# ATSAM4LC2B register map
Vendor: Atmel Corporation; Series: SAM4L; File version: B
CPU: CM4 r0p1, little endian, MPU, no FPU, 4 interrupt priority bits
Registers are 32-bit, write-only, reset 0x0 unless marked. A register's access mark holds for its fields unless they carry their own. Offsets are from the block's base; [hi:lo] are bit positions; {n}, {i} and the like mark numbered series; 'fields as' and 'values as' point back to an identical list.

## USART0 — Universal Synchronous Asynchronous Receiver Transmitter 0
Base 0x40024000; register names take the prefix USART_
Same registers: USART1 0x40028000, USART2 0x4002C000, USART3 0x40030000
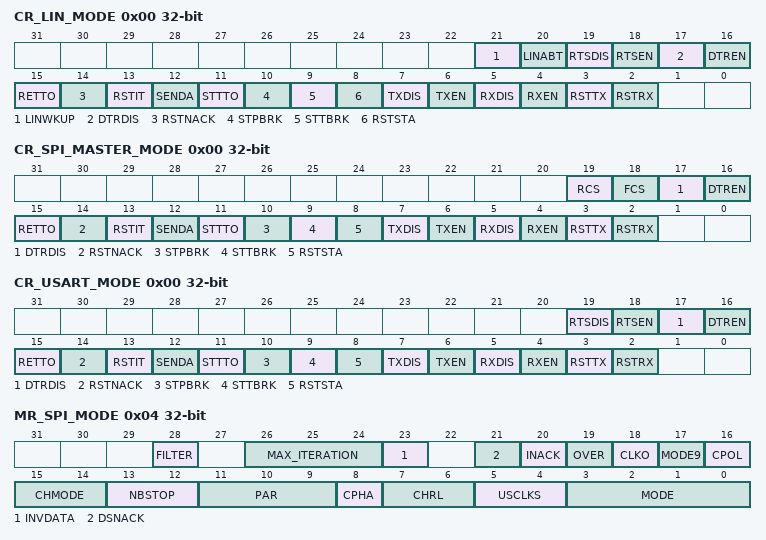
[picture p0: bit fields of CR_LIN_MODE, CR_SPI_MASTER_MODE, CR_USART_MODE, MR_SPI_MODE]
0x00 CR_LIN_MODE (alternate view of CR) — Control Register
  [21] LINWKUP — Sends a wakeup signal on the LIN bus
  [20] LINABT — Abort the current LIN transmission
  [19] RTSDIS — Request to Send Disable
    0=No effect; 1=Drives the pin RTS to 1
  [18] RTSEN — Request to Send Enable
    0=No effect; 1=Drives the pin RTS to 0
  [17] DTRDIS — Data Terminal Ready Disable
    0=No effect; 1=Drives the pin DTR to 1
  [16] DTREN — Data Terminal Ready Enable
    0=No effect; 1=Drives the pin DTR at 0
  [15] RETTO — Rearm Time-out
    0=No effect; 1=Restart Time-out
  [14] RSTNACK — Reset Non Acknowledge
    0=No effect; 1=Resets NACK in CSR
  [13] RSTIT — Reset Iterations
    0=No effect; 1=Resets ITERATION in CSR. No effect if the ISO7816 is not enabled
  [12] SENDA — Send Address
    0=No effect; 1=In Multi-drop Mode only, the next character written to the THR is sent with the address bit set
  [11] STTTO — Start Time-out
    0=No effect; 1=Starts waiting for a character before clocking the time-out counter
  [10] STPBRK — Stop Break
    0=No effect; 1=Stops transmission of the break after a minimum of one character length and transmits a high level during 12-bit periods.No effect if no break is being transmitted
  [9] STTBRK — Start Break
    0=No effect; 1=Starts transmission of a break after the characters present in THR and the Transmit Shift Register have been transmitted. No effect if a break is already being transmitted
  [8] RSTSTA — Reset Status Bits
    0=No effect; 1=Resets the status bits PARE, FRAME, OVRE and RXBRK in the CSR
  [7] TXDIS — Transmitter Disable
    0=No effect; 1=Disables the transmitter
  [6] TXEN — Transmitter Enable
    0=No effect; 1=Enables the transmitter if TXDIS is 0
  [5] RXDIS — Receiver Disable
    0=No effect; 1=Disables the receiver
  [4] RXEN — Receiver Enable
    0=No effect; 1=Enables the receiver, if RXDIS is 0
  [3] RSTTX — Reset Transmitter
    0=No effect; 1=Resets the transmitter
  [2] RSTRX — Reset Receiver
    0=No effect; 1=Resets the receiver
0x00 CR_SPI_MASTER_MODE (alternate view of CR) — Control Register
  [19] RCS — Release SPI Chip Select
    0=No effect; 1=Releases the Slave Select Line NSS (RTS pin)
  [18] FCS — Force SPI Chip Select
    0=No effect; 1=Forces the Slave Select Line NSS (RTS pin) to 0, even if USART is no transmitting, in order to address SPI slave devices supporting the CSAAT Mode (Chip Select Active After Transfer)
  [17] DTRDIS — Data Terminal Ready Disable
    0=No effect; 1=Drives the pin DTR to 1
  [16] DTREN — Data Terminal Ready Enable
    0=No effect; 1=Drives the pin DTR at 0
  [15] RETTO — Rearm Time-out
    0=No effect; 1=Restart Time-out
  [14] RSTNACK — Reset Non Acknowledge
    0=No effect; 1=Resets NACK in CSR
  [13] RSTIT — Reset Iterations
    values as CR_LIN_MODE.RSTIT
  [12] SENDA — Send Address
    values as CR_LIN_MODE.SENDA
  [11] STTTO — Start Time-out
    values as CR_LIN_MODE.STTTO
  [10] STPBRK — Stop Break
    values as CR_LIN_MODE.STPBRK
  [9] STTBRK — Start Break
    values as CR_LIN_MODE.STTBRK
  [8] RSTSTA — Reset Status Bits
    values as CR_LIN_MODE.RSTSTA
  [7] TXDIS — Transmitter Disable
    0=No effect; 1=Disables the transmitter
  [6] TXEN — Transmitter Enable
    0=No effect; 1=Enables the transmitter if TXDIS is 0
  [5] RXDIS — Receiver Disable
    0=No effect; 1=Disables the receiver
  [4] RXEN — Receiver Enable
    0=No effect; 1=Enables the receiver, if RXDIS is 0
  [3] RSTTX — Reset Transmitter
    0=No effect; 1=Resets the transmitter
  [2] RSTRX — Reset Receiver
    0=No effect; 1=Resets the receiver
0x00 CR_USART_MODE (alternate view of CR) — Control Register
  [19] RTSDIS — Request to Send Disable
    0=No effect; 1=Drives the pin RTS to 1
  [18] RTSEN — Request to Send Enable
    0=No effect; 1=Drives the pin RTS to 0
  [17] DTRDIS — Data Terminal Ready Disable
    0=No effect; 1=Drives the pin DTR to 1
  [16] DTREN — Data Terminal Ready Enable
    0=No effect; 1=Drives the pin DTR at 0
  [15] RETTO — Rearm Time-out
    0=No effect; 1=Restart Time-out
  [14] RSTNACK — Reset Non Acknowledge
    0=No effect; 1=Resets NACK in CSR
  [13] RSTIT — Reset Iterations
    values as CR_LIN_MODE.RSTIT
  [12] SENDA — Send Address
    values as CR_LIN_MODE.SENDA
  [11] STTTO — Start Time-out
    values as CR_LIN_MODE.STTTO
  [10] STPBRK — Stop Break
    values as CR_LIN_MODE.STPBRK
  [9] STTBRK — Start Break
    values as CR_LIN_MODE.STTBRK
  [8] RSTSTA — Reset Status Bits
    values as CR_LIN_MODE.RSTSTA
  [7] TXDIS — Transmitter Disable
    0=No effect; 1=Disables the transmitter
  [6] TXEN — Transmitter Enable
    0=No effect; 1=Enables the transmitter if TXDIS is 0
  [5] RXDIS — Receiver Disable
    0=No effect; 1=Disables the receiver
  [4] RXEN — Receiver Enable
    0=No effect; 1=Enables the receiver, if RXDIS is 0
  [3] RSTTX — Reset Transmitter
    0=No effect; 1=Resets the transmitter
  [2] RSTRX — Reset Receiver
    0=No effect; 1=Resets the receiver
0x04 MR_SPI_MODE rw (alternate view of MR) — Mode Register
  [28] FILTER — Infrared Receive Line Filter
    0=The USART does not filter the receive line; 1=The USART filters the receive line using a three-sample filter (1/16-bit clock) (2 over 3 majority)
  [26:24] MAX_ITERATION — Max interation
  [23] INVDATA — Inverted data
  [21] DSNACK — Disable Successive NACK
    0=NACK is sent on the ISO line as soon as a parity error occurs in the received character (unless INACK is set); 1=Successive parity errors are counted up to the value specified in the MAX_ITERATION field. These parity errors generatea NACK on the ISO line. As soon as this value is reached, no additional NACK is sent on the ISO line. The flag ITERATION is asserted
  [20] INACK — Inhibit Non Acknowledge
    0=The NACK is generated; 1=The NACK is not generated
  [19] OVER — Oversampling Mode
    0=X16 (16x Oversampling); 1=X8 (8x Oversampling)
  [18] CLKO — Clock Output Select
    0=The USART does not drive the SCK pin; 1=The USART drives the SCK pin if USCLKS does not select the external clock SCK
  [17] MODE9 — 9-bit Character Length
    0=CHRL defines character length; 1=9-bit character length
  [16] CPOL — SPI Clock Polarity
    0=ZERO (The inactive state value of SPCK is logic level zero); 1=ONE (The inactive state value of SPCK is logic level one)
  [15:14] CHMODE — Channel Mode
    0=NORMAL (Normal Mode); 1=ECHO (Automatic Echo. Receiver input is connected to the TXD pin); 2=LOCAL_LOOP (Local Loopback. Transmitter output is connected to the Receiver Input); 3=REMOTE_LOOP (Remote Loopback. RXD pin is internally connected to the TXD pin)
  [13:12] NBSTOP — Number of Stop Bits
    0=1 stop bit; 1=1_5 (1.5 stop bits (Only valid if SYNC=0)); 2=2 stop bits
  [11:9] PAR — Parity Type
    0=EVEN (Even parity); 1=ODD (Odd parity); 2=SPACE (Parity forced to 0 (Space)); 3=MARK (Parity forced to 1 (Mark)); 4=NONE (No Parity); 5=No Parity; 6=MULTI (Multi-drop mode); 7=Multi-drop mode
  [8] CPHA — SPI CLock Phase
    0=Data is changed on the leading edge of SPCK and captured on the following edge of SPCK; 1=Data is captured on the leading edge of SPCK and changed on the following edge of SPCK
  [7:6] CHRL — Character Length.
    {v}={v+5} bits (v=0..3)
  [5:4] USCLKS — Clock Selection
    0=MCK; 1=MCK_DIV; 3=SCK
  [3:0] MODE — Usart Mode
    0=NORMAL; 1=RS485; 2=HARDWARE (Hardware Handshaking); 3=MODEM; 4=ISO7816_T0 (IS07816 Protocol: T = 0); 6=ISO7816_T1 (IS07816 Protocol: T = 1); 8=IRDA; 10=LIN_Master; 11=LIN_Slave; 14=SPI_Master; 15=SPI_Slave
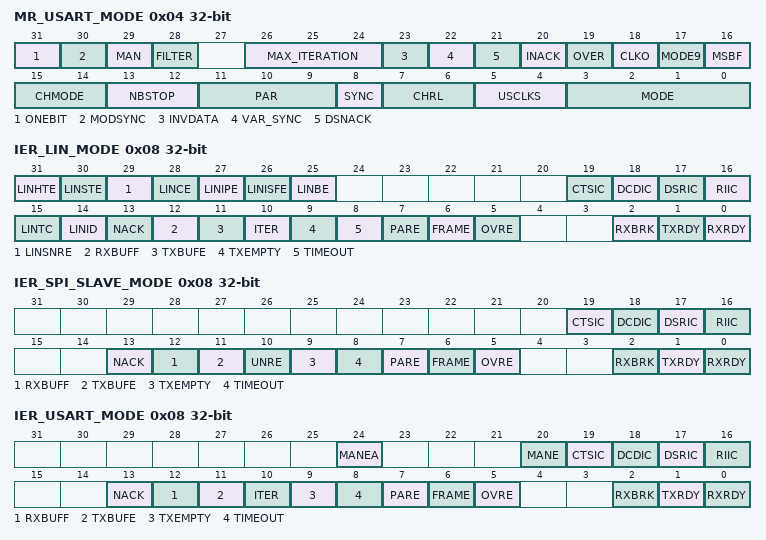
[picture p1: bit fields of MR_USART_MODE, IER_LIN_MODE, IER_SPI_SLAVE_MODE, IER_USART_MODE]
0x04 MR_USART_MODE rw (alternate view of MR) — Mode Register
  [31] ONEBIT — Start Frame Delimiter selector
    0=Start Frame delimiter is COMMAND or DATA SYNC; 1=Start Frame delimiter is One Bit
  [30] MODSYNC — Manchester Synchronization Mode
    0=The Manchester Start bit is a 0 to 1 transition; 1=The Manchester Start bit is a 1 to 0 transition
  [29] MAN — Manchester Encoder/Decoder Enable
    0=Manchester Encoder/Decoder is disabled; 1=Manchester Encoder/Decoder is enabled
  [28] FILTER — Infrared Receive Line Filter
    values as MR_SPI_MODE.FILTER
  [26:24] MAX_ITERATION — Max interation
  [23] INVDATA — Inverted data
  [22] VAR_SYNC — Variable synchronization of command/data sync Start Frame Delimiter
    0=User defined configuration of command or data sync field depending on SYNC value; 1=The sync field is updated when a character is written into THR register
  [21] DSNACK — Disable Successive NACK
    values as MR_SPI_MODE.DSNACK
  [20] INACK — Inhibit Non Acknowledge
    0=The NACK is generated; 1=The NACK is not generated
  [19] OVER — Oversampling Mode
    0=X16 (16x Oversampling); 1=X8 (8x Oversampling)
  [18] CLKO — Clock Output Select
    values as MR_SPI_MODE.CLKO
  [17] MODE9 — 9-bit Character Length
    0=CHRL defines character length; 1=9-bit character length
  [16] MSBF — Bit Order
    0=LSBF (Least Significant Bit first); 1=MSBF (Most Significant Bit first)
  [15:14] CHMODE — Channel Mode
    values as MR_SPI_MODE.CHMODE
  [13:12] NBSTOP — Number of Stop Bits
    values as MR_SPI_MODE.NBSTOP
  [11:9] PAR — Parity Type
    values as MR_SPI_MODE.PAR
  [8] SYNC — Synchronous Mode Select
    0=USART operates in Synchronous Mode; 1=USART operates in Asynchronous Mode
  [7:6] CHRL — Character Length.
    {v}={v+5} bits (v=0..3)
  [5:4] USCLKS — Clock Selection
    0=MCK; 1=MCK_DIV; 3=SCK
  [3:0] MODE — Usart Mode
    values as MR_SPI_MODE.MODE
0x08 IER_LIN_MODE (alternate view of IER) — Interrupt Enable Register
  [31] LINHTE — LIN Header Timeout Error Interrupt Enable
    0=No Effect; 1=Enables the interrupt
  [30] LINSTE — LIN Synch Tolerance Error Interrupt Enable
    0=No Effect; 1=Enables the interrupt
  [29] LINSNRE — LIN Slave Not Responding Error Interrupt Enable
  [28] LINCE — LIN Checksum Error Interrupt Enable
  [27] LINIPE — LIN Identifier Parity Interrupt Enable
  [26] LINISFE — LIN Inconsistent Synch Field Error Interrupt Enable
  [25] LINBE — LIN Bus Error Interrupt Enable
  [19] CTSIC — Clear to Send Input Change Interrupt Enable
    0=No Effect; 1=Enables the interrupt
  [18] DCDIC — Data Carrier Detect Input Change Interrupt Enable
    0=No Effect; 1=Enables the interrupt
  [17] DSRIC — Data Set Ready Input Change Enable
    0=No Effect; 1=Enables the interrupt
  [16] RIIC — Ring Indicator Input Change Enable
    0=No Effect; 1=Enables the interrupt
  [15] LINTC — LIN Transfer Conpleted Interrupt Enable
  [14] LINID — LIN Identifier Sent or LIN Identifier Received Interrupt Enable
  [13] NACK — Non Acknowledge or LIN Break Sent or LIN Break Received Interrupt Enable
    0=No Effect; 1=Enables the interrupt
  [12] RXBUFF — Buffer Full Interrupt Enable
    0=No Effect; 1=Enables the interrupt
  [11] TXBUFE — Buffer Empty Interrupt Enable
    0=No Effect; 1=Enables the interrupt
  [10] ITER — Iteration Interrupt Enable
    0=No Effect; 1=Enables the interrupt
  [9] TXEMPTY — Transmitter Empty Interrupt Enable
    0=No Effect; 1=Enables the interrupt
  [8] TIMEOUT — Time-out Interrupt Enable
    0=No Effect; 1=Enables the interrupt
  [7] PARE — Parity Error Interrupt Enable
    0=No Effect; 1=Enables the interrupt
  [6] FRAME — Framing Error Interrupt Enable
    0=No Effect; 1=Enables the interrupt
  [5] OVRE — Overrun Error Interrupt Enable
    0=No Effect; 1=Enables the interrupt
  [2] RXBRK — Receiver Break Interrupt Enable
    0=No Effect; 1=Enables the interrupt
  [1] TXRDY — Transmitter Ready Interrupt Enable
    0=No Effect; 1=Enables the interrupt
  [0] RXRDY — Receiver Ready Interrupt Enable
    0=No Effect; 1=Enables the interrupt
0x08 IER_SPI_SLAVE_MODE (alternate view of IER) — Interrupt Enable Register
  [all] fields
    0=No Effect; 1=Enables the interrupt
  [19] CTSIC — Clear to Send Input Change Interrupt Enable
  [18] DCDIC — Data Carrier Detect Input Change Interrupt Enable
  [17] DSRIC — Data Set Ready Input Change Enable
  [16] RIIC — Ring Indicator Input Change Enable
  [13] NACK — Non Acknowledge Interrupt Enable
  [12] RXBUFF — Buffer Full Interrupt Enable
  [11] TXBUFE — Buffer Empty Interrupt Enable
  [10] UNRE — SPI Underrun Error Interrupt Enable
  [9] TXEMPTY — Transmitter Empty Interrupt Enable
  [8] TIMEOUT — Time-out Interrupt Enable
  [7] PARE — Parity Error Interrupt Enable
  [6] FRAME — Framing Error Interrupt Enable
  [5] OVRE — Overrun Error Interrupt Enable
  [2] RXBRK — Receiver Break Interrupt Enable
  [1] TXRDY — Transmitter Ready Interrupt Enable
  [0] RXRDY — Receiver Ready Interrupt Enable
0x08 IER_USART_MODE (alternate view of IER) — Interrupt Enable Register
  [24] MANEA — Manchester Error Interrupt Enable
    0=No effect; 1=Enables the interrupt
  [20] MANE — Manchester Error Interrupt Enable
  [19] CTSIC — Clear to Send Input Change Interrupt Enable
    0=No Effect; 1=Enables the interrupt
  [18] DCDIC — Data Carrier Detect Input Change Interrupt Enable
    0=No Effect; 1=Enables the interrupt
  [17] DSRIC — Data Set Ready Input Change Enable
    0=No Effect; 1=Enables the interrupt
  [16] RIIC — Ring Indicator Input Change Enable
    0=No Effect; 1=Enables the interrupt
  [13] NACK — Non Acknowledge Interrupt Enable
    0=No Effect; 1=Enables the interrupt
  [12] RXBUFF — Buffer Full Interrupt Enable
    0=No Effect; 1=Enables the interrupt
  [11] TXBUFE — Buffer Empty Interrupt Enable
    0=No Effect; 1=Enables the interrupt
  [10] ITER — Iteration Interrupt Enable
    0=No Effect; 1=Enables the interrupt
  [9] TXEMPTY — Transmitter Empty Interrupt Enable
    0=No Effect; 1=Enables the interrupt
  [8] TIMEOUT — Time-out Interrupt Enable
    0=No Effect; 1=Enables the interrupt
  [7] PARE — Parity Error Interrupt Enable
    0=No Effect; 1=Enables the interrupt
  [6] FRAME — Framing Error Interrupt Enable
    0=No Effect; 1=Enables the interrupt
  [5] OVRE — Overrun Error Interrupt Enable
    0=No Effect; 1=Enables the interrupt
  [2] RXBRK — Receiver Break Interrupt Enable
    0=No Effect; 1=Enables the interrupt
  [1] TXRDY — Transmitter Ready Interrupt Enable
    0=No Effect; 1=Enables the interrupt
  [0] RXRDY — Receiver Ready Interrupt Enable
    0=No Effect; 1=Enables the interrupt
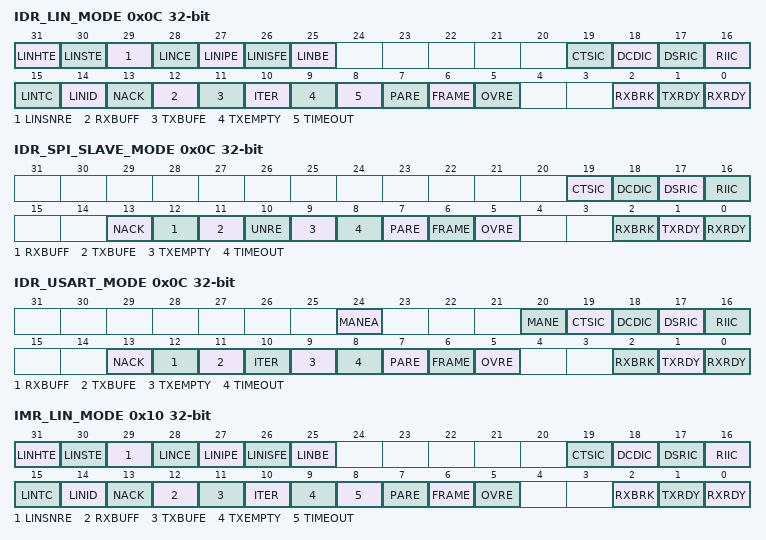
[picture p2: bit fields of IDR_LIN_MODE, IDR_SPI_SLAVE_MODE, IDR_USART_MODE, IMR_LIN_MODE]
0x0C IDR_LIN_MODE (alternate view of IDR) — Interrupt Disable Register
  [31] LINHTE — LIN Header Timeout Error Interrupt Disable
    0=No Effect; 1=Disables the interrupt
  [30] LINSTE — LIN Synch Tolerance Error Interrupt Disable
    0=No Effect; 1=Disables the interrupt
  [29] LINSNRE — LIN Slave Not Responding Error Interrupt Disable
  [28] LINCE — LIN Checksum Error Interrupt Disable
  [27] LINIPE — LIN Identifier Parity Interrupt Disable
  [26] LINISFE — LIN Inconsistent Synch Field Error Interrupt Disable
  [25] LINBE — LIN Bus Error Interrupt Disable
  [19] CTSIC — Clear to Send Input Change Interrupt Disable
    0=No Effect; 1=Disables the interrupt
  [18] DCDIC — Data Carrier Detect Input Change Interrupt Disable
    0=No Effect; 1=Disables the interrupt
  [17] DSRIC — Data Set Ready Input Change Disable
    0=No Effect; 1=Disables the interrupt
  [16] RIIC — Ring Indicator Input Change Disable
    0=No Effect; 1=Disables the interrupt
  [15] LINTC — LIN Transfer Conpleted Interrupt Disable
  [14] LINID — LIN Identifier Sent or LIN Identifier Received Interrupt Disable
  [13] NACK — Non Acknowledge or LIN Break Sent or LIN Break Received Interrupt Disable
    0=No Effect; 1=Disables the interrupt
  [12] RXBUFF — Buffer Full Interrupt Disable
    0=No Effect; 1=Disables the interrupt
  [11] TXBUFE — Buffer Empty Interrupt Disable
    0=No Effect; 1=Disables the interrupt
  [10] ITER — Iteration Interrupt Disable
    0=No Effect; 1=Disables the interrupt
  [9] TXEMPTY — Transmitter Empty Interrupt Disable
    0=No Effect; 1=Disables the interrupt
  [8] TIMEOUT — Time-out Interrupt Disable
    0=No Effect; 1=Disables the interrupt
  [7] PARE — Parity Error Interrupt Disable
    0=No Effect; 1=Disables the interrupt
  [6] FRAME — Framing Error Interrupt Disable
    0=No Effect; 1=Disables the interrupt
  [5] OVRE — Overrun Error Interrupt Disable
    0=No Effect; 1=Disables the interrupt
  [2] RXBRK — Receiver Break Interrupt Disable
    0=No Effect; 1=Disables the interrupt
  [1] TXRDY — Transmitter Ready Interrupt Disable
    0=No Effect; 1=Disables the interrupt
  [0] RXRDY — Receiver Ready Interrupt Disable
    0=No Effect; 1=Disables the interrupt
0x0C IDR_SPI_SLAVE_MODE (alternate view of IDR) — Interrupt Disable Register
  [all] fields
    0=No Effect; 1=Disables the interrupt
  [19] CTSIC — Clear to Send Input Change Interrupt Disable
  [18] DCDIC — Data Carrier Detect Input Change Interrupt Disable
  [17] DSRIC — Data Set Ready Input Change Disable
  [16] RIIC — Ring Indicator Input Change Disable
  [13] NACK — Non Acknowledge Interrupt Disable
  [12] RXBUFF — Buffer Full Interrupt Disable
  [11] TXBUFE — Buffer Empty Interrupt Disable
  [10] UNRE — SPI Underrun Error Interrupt Disable
  [9] TXEMPTY — Transmitter Empty Interrupt Disable
  [8] TIMEOUT — Time-out Interrupt Disable
  [7] PARE — Parity Error Interrupt Disable
  [6] FRAME — Framing Error Interrupt Disable
  [5] OVRE — Overrun Error Interrupt Disable
  [2] RXBRK — Receiver Break Interrupt Disable
  [1] TXRDY — Transmitter Ready Interrupt Disable
  [0] RXRDY — Receiver Ready Interrupt Disable
0x0C IDR_USART_MODE (alternate view of IDR) — Interrupt Disable Register
  [24] MANEA — Manchester Error Interrupt Disable
    0=No effect; 1=Disables the corresponding interrupt
  [20] MANE — Manchester Error Interrupt Disable
  [19] CTSIC — Clear to Send Input Change Interrupt Disable
    0=No Effect; 1=Disables the interrupt
  [18] DCDIC — Data Carrier Detect Input Change Interrupt Disable
    0=No Effect; 1=Disables the interrupt
  [17] DSRIC — Data Set Ready Input Change Disable
    0=No Effect; 1=Disables the interrupt
  [16] RIIC — Ring Indicator Input Change Disable
    0=No Effect; 1=Disables the interrupt
  [13] NACK — Non Acknowledge Interrupt Disable
    0=No Effect; 1=Disables the interrupt
  [12] RXBUFF — Buffer Full Interrupt Disable
    0=No Effect; 1=Disables the interrupt
  [11] TXBUFE — Buffer Empty Interrupt Disable
    0=No Effect; 1=Disables the interrupt
  [10] ITER — Iteration Interrupt Disable
    0=No Effect; 1=Disables the interrupt
  [9] TXEMPTY — Transmitter Empty Interrupt Disable
    0=No Effect; 1=Disables the interrupt
  [8] TIMEOUT — Time-out Interrupt Disable
    0=No Effect; 1=Disables the interrupt
  [7] PARE — Parity Error Interrupt Disable
    0=No Effect; 1=Disables the interrupt
  [6] FRAME — Framing Error Interrupt Disable
    0=No Effect; 1=Disables the interrupt
  [5] OVRE — Overrun Error Interrupt Disable
    0=No Effect; 1=Disables the interrupt
  [2] RXBRK — Receiver Break Interrupt Disable
    0=No Effect; 1=Disables the interrupt
  [1] TXRDY — Transmitter Ready Interrupt Disable
    0=No Effect; 1=Disables the interrupt
  [0] RXRDY — Receiver Ready Interrupt Disable
    0=No Effect; 1=Disables the interrupt
0x10 IMR_LIN_MODE ro (alternate view of IMR) — Interrupt Mask Register
  [31] LINHTE — LIN Header Timeout Error Interrupt Mask
    0=The interrupt is disabled; 1=The interrupt is enabled
  [30] LINSTE — LIN Synch Tolerance Error Interrupt Mask
    0=The interrupt is disabled; 1=The interrupt is enabled
  [29] LINSNRE — LIN Slave Not Responding Error Interrupt Mask
  [28] LINCE — LIN Checksum Error Interrupt Mask
  [27] LINIPE — LIN Identifier Parity Interrupt Mask
  [26] LINISFE — LIN Inconsistent Synch Field Error Interrupt Mask
  [25] LINBE — LIN Bus Error Interrupt Mask
  [19] CTSIC — Clear to Send Input Change Interrupt Mask
    0=The interrupt is disabled; 1=The interrupt is enabled
  [18] DCDIC — Data Carrier Detect Input Change Interrupt Mask
    0=The interrupt is disabled; 1=The interrupt is enabled
  [17] DSRIC — Data Set Ready Input Change Mask
    0=The interrupt is disabled; 1=The interrupt is enabled
  [16] RIIC — Ring Indicator Input Change Mask
    0=The interrupt is disabled; 1=The interrupt is enabled
  [15] LINTC — LIN Transfer Conpleted Interrupt Mask
  [14] LINID — LIN Identifier Sent or LIN Received Interrupt Mask
  [13] NACK — Non Acknowledge or LIN Break Sent or LIN Break Received Interrupt Mask
    0=The interrupt is disabled; 1=The interrupt is enabled
  [12] RXBUFF — Buffer Full Interrupt Mask
    0=The interrupt is disabled; 1=The interrupt is enabled
  [11] TXBUFE — Buffer Empty Interrupt Mask
    0=The interrupt is disabled; 1=The interrupt is enabled
  [10] ITER — Iteration Interrupt Mask
    0=The interrupt is disabled; 1=The interrupt is enabled
  [9] TXEMPTY — TXEMPTY Interrupt Mask
    0=The interrupt is disabled; 1=The interrupt is enabled
  [8] TIMEOUT — Time-out Interrupt Mask
    0=The interrupt is disabled; 1=The interrupt is enabled
  [7] PARE — Parity Error Interrupt Mask
    0=The interrupt is disabled; 1=The interrupt is enabled
  [6] FRAME — Framing Error Interrupt Mask
    0=The interrupt is disabled; 1=The interrupt is enabled
  [5] OVRE — Overrun Error Interrupt Mask
    0=The interrupt is disabled; 1=The interrupt is enabled
  [2] RXBRK — Receiver Break Interrupt Mask
    0=The interrupt is disabled; 1=The interrupt is enabled
  [1] TXRDY — TXRDY Interrupt Mask
    0=The interrupt is disabled; 1=The interrupt is enabled
  [0] RXRDY — RXRDY Interrupt Mask
    0=The interrupt is disabled; 1=The interrupt is enabled
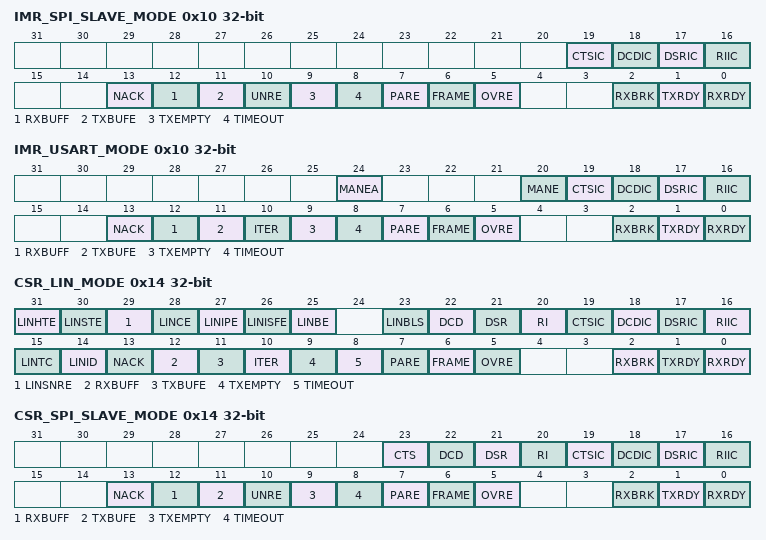
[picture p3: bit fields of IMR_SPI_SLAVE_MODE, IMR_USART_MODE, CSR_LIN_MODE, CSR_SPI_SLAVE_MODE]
0x10 IMR_SPI_SLAVE_MODE ro (alternate view of IMR) — Interrupt Mask Register
  [all] fields
    0=The interrupt is disabled; 1=The interrupt is enabled
  [19] CTSIC — Clear to Send Input Change Interrupt Mask
  [18] DCDIC — Data Carrier Detect Input Change Interrupt Mask
  [17] DSRIC — Data Set Ready Input Change Mask
  [16] RIIC — Ring Indicator Input Change Mask
  [13] NACK — Non Acknowledge Interrupt Mask
  [12] RXBUFF — Buffer Full Interrupt Mask
  [11] TXBUFE — Buffer Empty Interrupt Mask
  [10] UNRE — SPI Underrun Error Interrupt Mask
  [9] TXEMPTY — TXEMPTY Interrupt Mask
  [8] TIMEOUT — Time-out Interrupt Mask
  [7] PARE — Parity Error Interrupt Mask
  [6] FRAME — Framing Error Interrupt Mask
  [5] OVRE — Overrun Error Interrupt Mask
  [2] RXBRK — Receiver Break Interrupt Mask
  [1] TXRDY — TXRDY Interrupt Mask
  [0] RXRDY — RXRDY Interrupt Mask
0x10 IMR_USART_MODE ro (alternate view of IMR) — Interrupt Mask Register
  [24] MANEA — Manchester Error Interrupt Mask
    0=The interrupt is disabled; 1=The interrupt is enabled
  [20] MANE — Manchester Error Interrupt Mask
  [19] CTSIC — Clear to Send Input Change Interrupt Mask
    0=The interrupt is disabled; 1=The interrupt is enabled
  [18] DCDIC — Data Carrier Detect Input Change Interrupt Mask
    0=The interrupt is disabled; 1=The interrupt is enabled
  [17] DSRIC — Data Set Ready Input Change Mask
    0=The interrupt is disabled; 1=The interrupt is enabled
  [16] RIIC — Ring Indicator Input Change Mask
    0=The interrupt is disabled; 1=The interrupt is enabled
  [13] NACK — Non Acknowledge Interrupt Mask
    0=The interrupt is disabled; 1=The interrupt is enabled
  [12] RXBUFF — Buffer Full Interrupt Mask
    0=The interrupt is disabled; 1=The interrupt is enabled
  [11] TXBUFE — Buffer Empty Interrupt Mask
    0=The interrupt is disabled; 1=The interrupt is enabled
  [10] ITER — Iteration Interrupt Mask
    0=The interrupt is disabled; 1=The interrupt is enabled
  [9] TXEMPTY — TXEMPTY Interrupt Mask
    0=The interrupt is disabled; 1=The interrupt is enabled
  [8] TIMEOUT — Time-out Interrupt Mask
    0=The interrupt is disabled; 1=The interrupt is enabled
  [7] PARE — Parity Error Interrupt Mask
    0=The interrupt is disabled; 1=The interrupt is enabled
  [6] FRAME — Framing Error Interrupt Mask
    0=The interrupt is disabled; 1=The interrupt is enabled
  [5] OVRE — Overrun Error Interrupt Mask
    0=The interrupt is disabled; 1=The interrupt is enabled
  [2] RXBRK — Receiver Break Interrupt Mask
    0=The interrupt is disabled; 1=The interrupt is enabled
  [1] TXRDY — TXRDY Interrupt Mask
    0=The interrupt is disabled; 1=The interrupt is enabled
  [0] RXRDY — RXRDY Interrupt Mask
    0=The interrupt is disabled; 1=The interrupt is enabled
0x14 CSR_LIN_MODE ro (alternate view of CSR) — Channel Status Register
  [31] LINHTE — LIN Header Timeout Error
    0=COMM_RX is at 0; 1=COMM_RX is at 1
  [30] LINSTE — LIN Synch Tolerance Error
    0=COMM_TX is at 0; 1=COMM_TX is at 1
  [29] LINSNRE — LIN Slave Not Responding Error
  [28] LINCE — LIN Checksum Error
  [27] LINIPE — LIN Identifier Parity Error
  [26] LINISFE — LIN Inconsistent Synch Field Error
  [25] LINBE — LIN Bit Error
  [23] LINBLS — LIN Bus Line Status
    0=CTS is at 0; 1=CTS is at 1
  [22] DCD — Image of DCD Input
    0=DCD is at 0; 1=DCD is at 1
  [21] DSR — Image of DSR Input
    0=DSR is at 0; 1=DSR is at 1
  [20] RI — Image of RI Input
    0=RI is at 0; 1=RI is at 1
  [19] CTSIC — Clear to Send Input Change Flag
    0=No input change has been detected on the CTS pin since the last read of CSR; 1=At least one input change has been detected on the CTS pin since the last read of CSR
  [18] DCDIC — Data Carrier Detect Input Change Flag
    0=No input change has been detected on the DCD pin since the last read of CSR; 1=At least one input change has been detected on the DCD pin since the last read of CSR
  [17] DSRIC — Data Set Ready Input Change Flag
    0=No input change has been detected on the DSR pin since the last read of CSR; 1=At least one input change has been detected on the DSR pin since the last read of CSR
  [16] RIIC — Ring Indicator Input Change Flag
    0=No input change has been detected on the RI pin since the last read of CSR; 1=At least one input change has been detected on the RI pin since the last read of CSR
  [15] LINTC — LIN Transfer Conpleted
  [14] LINID — LIN Identifier Sent or LIN Identifier Received
  [13] NACK — Non Acknowledge or LIN Break Sent or LIN Break Received
    0=No Non Acknowledge has not been detected since the last RSTNACK; 1=At least one Non Acknowledge has been detected since the last RSTNACK
  [12] RXBUFF — Reception Buffer Full
    0=The signal Buffer Full from the Receive PDC channel is inactive; 1=The signal Buffer Full from the Receive PDC channel is active
  [11] TXBUFE — Transmission Buffer Empty
    0=The signal Buffer Empty from the Transmit PDC channel is inactive; 1=The signal Buffer Empty from the Transmit PDC channel is active
  [10] ITER — Max number of Repetitions Reached
    0=Maximum number of repetitions has not been reached since the last RSIT; 1=Maximum number of repetitions has been reached since the last RSIT
  [9] TXEMPTY — Transmitter Empty
    0=There are characters in either THR or the Transmit Shift Register, or the transmitter is disabled; 1=There is at least one character in either THR or the Transmit Shift Register
  [8] TIMEOUT — Receiver Time-out
    0=There has not been a time-out since the last Start Time-out command or the Time-out Register is 0; 1=There has been a time-out since the last Start Time-out command
  [7] PARE — Parity Error
    0=No parity error has been detected since the last RSTSTA; 1=At least one parity error has been detected since the last RSTSTA
  [6] FRAME — Framing Error
    0=No stop bit has been detected low since the last RSTSTA; 1=At least one stop bit has been detected low since the last RSTSTA
  [5] OVRE — Overrun Error
    0=No overrun error has occurred since since the last RSTSTA; 1=At least one overrun error has occurred since the last RSTSTA
  [2] RXBRK — Break Received/End of Break
    0=No Break received or End of Break detected since the last RSTSTA; 1=Break Received or End of Break detected since the last RSTSTA
  [1] TXRDY — Transmitter Ready
    0=A character is in the THR waiting to be transferred to the Transmit Shift Register, or an STTBRK command has been requested, or the transmitter is disabled. As soon as the transmitter is enabled, TXRDY becomes 1; 1=There is no character in the THR
  [0] RXRDY — Receiver Ready
    0=No complete character has been received since the last read of RHR or the receiver is disabled. If characters werebeing received when the receiver was disabled, RXRDY changes to 1 when the receiver is enabled; 1=At least one complete character has been received and RHR has not yet been read
0x14 CSR_SPI_SLAVE_MODE ro (alternate view of CSR) — Channel Status Register
  [23] CTS — Image of CTS Input
    0=CTS is at 0; 1=CTS is at 1
  [22] DCD — Image of DCD Input
    0=DCD is at 0; 1=DCD is at 1
  [21] DSR — Image of DSR Input
    0=DSR is at 0; 1=DSR is at 1
  [20] RI — Image of RI Input
    0=RI is at 0; 1=RI is at 1
  [19] CTSIC — Clear to Send Input Change Flag
    values as CSR_LIN_MODE.CTSIC
  [18] DCDIC — Data Carrier Detect Input Change Flag
    values as CSR_LIN_MODE.DCDIC
  [17] DSRIC — Data Set Ready Input Change Flag
    values as CSR_LIN_MODE.DSRIC
  [16] RIIC — Ring Indicator Input Change Flag
    values as CSR_LIN_MODE.RIIC
  [13] NACK — Non Acknowledge
    values as CSR_LIN_MODE.NACK
  [12] RXBUFF — Reception Buffer Full
    values as CSR_LIN_MODE.RXBUFF
  [11] TXBUFE — Transmission Buffer Empty
    values as CSR_LIN_MODE.TXBUFE
  [10] UNRE — SPI Underrun Error
    0=No SPI underrun error has occurred since the last RSTSTA; 1=At least one SPI underrun error has occurred since the last RSTSTA
  [9] TXEMPTY — Transmitter Empty
    values as CSR_LIN_MODE.TXEMPTY
  [8] TIMEOUT — Receiver Time-out
    values as CSR_LIN_MODE.TIMEOUT
  [7] PARE — Parity Error
    values as CSR_LIN_MODE.PARE
  [6] FRAME — Framing Error
    values as CSR_LIN_MODE.FRAME
  [5] OVRE — Overrun Error
    values as CSR_LIN_MODE.OVRE
  [2] RXBRK — Break Received/End of Break
    values as CSR_LIN_MODE.RXBRK
  [1] TXRDY — Transmitter Ready
    values as CSR_LIN_MODE.TXRDY
  [0] RXRDY — Receiver Ready
    values as CSR_LIN_MODE.RXRDY
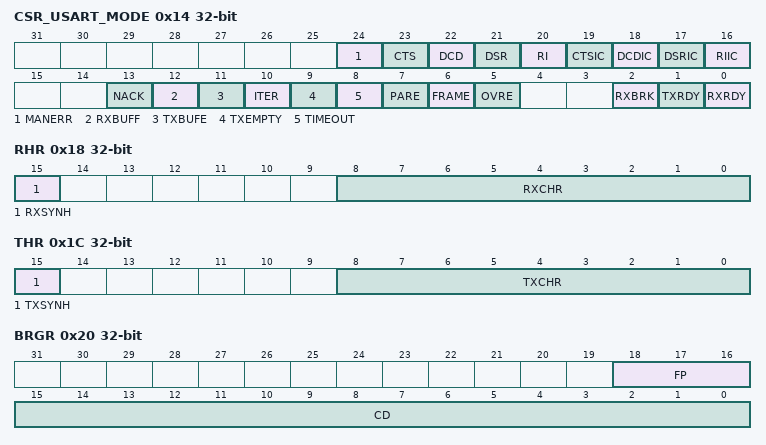
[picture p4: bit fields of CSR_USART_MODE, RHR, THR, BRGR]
0x14 CSR_USART_MODE ro (alternate view of CSR) — Channel Status Register
  [24] MANERR — Manchester Error
    0=No Manchester error has been detected since the last RSTSTA; 1=At least one Manchester error has been detected since the last RSTSTA
  [23] CTS — Image of CTS Input
    0=CTS is at 0; 1=CTS is at 1
  [22] DCD — Image of DCD Input
    0=DCD is at 0; 1=DCD is at 1
  [21] DSR — Image of DSR Input
    0=DSR is at 0; 1=DSR is at 1
  [20] RI — Image of RI Input
    0=RI is at 0; 1=RI is at 1
  [19] CTSIC — Clear to Send Input Change Flag
    values as CSR_LIN_MODE.CTSIC
  [18] DCDIC — Data Carrier Detect Input Change Flag
    values as CSR_LIN_MODE.DCDIC
  [17] DSRIC — Data Set Ready Input Change Flag
    values as CSR_LIN_MODE.DSRIC
  [16] RIIC — Ring Indicator Input Change Flag
    values as CSR_LIN_MODE.RIIC
  [13] NACK — Non Acknowledge
    values as CSR_LIN_MODE.NACK
  [12] RXBUFF — Reception Buffer Full
    values as CSR_LIN_MODE.RXBUFF
  [11] TXBUFE — Transmission Buffer Empty
    values as CSR_LIN_MODE.TXBUFE
  [10] ITER — Max number of Repetitions Reached
    values as CSR_LIN_MODE.ITER
  [9] TXEMPTY — Transmitter Empty
    values as CSR_LIN_MODE.TXEMPTY
  [8] TIMEOUT — Receiver Time-out
    values as CSR_LIN_MODE.TIMEOUT
  [7] PARE — Parity Error
    values as CSR_LIN_MODE.PARE
  [6] FRAME — Framing Error
    values as CSR_LIN_MODE.FRAME
  [5] OVRE — Overrun Error
    values as CSR_LIN_MODE.OVRE
  [2] RXBRK — Break Received/End of Break
    values as CSR_LIN_MODE.RXBRK
  [1] TXRDY — Transmitter Ready
    values as CSR_LIN_MODE.TXRDY
  [0] RXRDY — Receiver Ready
    values as CSR_LIN_MODE.RXRDY
0x18 RHR ro — Receiver Holding Register
  [15] RXSYNH — Received Sync
    0=Last character received is a Data; 1=Last character received is a Command
  [8:0] RXCHR — Received Character
0x1C THR — Transmitter Holding Register
  [15] TXSYNH — Sync Field to be transmitted
    0=The next character sent is encoded as a data. Start Frame Delimiter is DATA SYNC; 1=The next character sent is encoded as a command. Start Frame Delimiter is COMMAND SYNC
  [8:0] TXCHR — Character to be Transmitted
0x20 BRGR rw — Baud Rate Generator Register
  [18:16] FP — Fractional Part
    0=Fractional divider is disabled
  [15:0] CD — Clock Divisor
    0=DISABLE (Disables the clock); 1=BYPASS (Clock Divisor Bypass); 2=Baud Rate (Asynchronous Mode) = Selected Clock/(16 x CD) or (8 x CD); Baud Rate (Synchronous Mode) = Selected Clock/CD;
0x24 RTOR rw — Receiver Time-out Register
  [16:0] TO — Time-out Value
    0=DISABLE (Disables the RX Time-out function)
0x28 TTGR rw — Transmitter Timeguard Register
  [7:0] TG — Timeguard Value
    0=DISABLE (Disables the TX Timeguard function.)
0x40 FIDI rw reset 0x174 — FI DI Ratio Register
  [10:0] FI_DI_RATIO — FI Over DI Ratio Value
    0=DISABLE (Baud Rate = 0)
0x44 NER ro — Number of Errors Register
  [7:0] NB_ERRORS — Error number during ISO7816 transfers
0x4C IFR rw — IrDA Filter Register
  [7:0] IRDA_FILTER
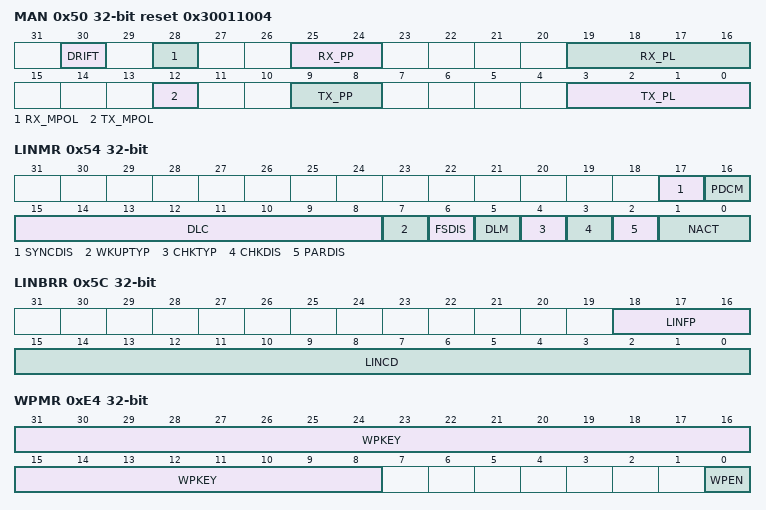
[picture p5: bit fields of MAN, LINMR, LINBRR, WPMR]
0x50 MAN rw reset 0x30011004 — Manchester Configuration Register
  [30] DRIFT — Drift compensation
    0=The USART can not recover from an important clock drift; 1=The USART can recover from clock drift. The 16X clock mode must be enabled
  [28] RX_MPOL — Receiver Manchester Polarity
    0=Logic Zero is coded as a zero-to-one transition, Logic One is coded as a one-to-zero transition; 1=Logic Zero is coded as a one-to-zero transition, Logic One is coded as a zero-to-one transition
  [25:24] RX_PP — Receiver Preamble Pattern detected
    0=ALL_ONE; 1=ALL_ZERO; 2=ZERO_ONE; 3=ONE_ZERO
  [19:16] RX_PL — Receiver Preamble Length
    0=The receiver preamble pattern detection is disabled
  [12] TX_MPOL — Transmitter Manchester Polarity
    values as RX_MPOL
  [9:8] TX_PP — Transmitter Preamble Pattern
    0=ALL_ONE; 1=ALL_ZERO; 2=ZERO_ONE; 3=ONE_ZERO
  [3:0] TX_PL — Transmitter Preamble Length
    0=The Transmitter Preamble pattern generation is disabled
0x54 LINMR rw — LIN Mode Register
  [17] SYNCDIS — Synchronization Disable
  [16] PDCM — PDC Mode
  [15:8] DLC — Data Length Control
  [7] WKUPTYP — Wakeup Signal Type
  [6] FSDIS — Frame Slot Mode Disable
  [5] DLM — Data Length Mode
  [4] CHKTYP — Checksum Type
  [3] CHKDIS — Checksum Disable
  [2] PARDIS — Parity Disable
  [1:0] NACT — LIN Node Action
    0=PUBLISH (The LIN Controller transmits the response); 1=SUBSCRIBE (The LIN Controller receives the response); 2=IGNORE (The LIN Controller doesn't transmit and doesn't receive the response)
0x58 LINIR rw — LIN Identifier Register
  [7:0] IDCHR — Identifier Character
0x5C LINBRR ro — LIN Baud Rate Register
  [18:16] LINFP — Fractional Part after Synchronization
  [15:0] LINCD — Clock Divider after Synchronization
0xE4 WPMR rw — Write Protect Mode Register
  [31:8] WPKEY — Write Protect Key
  [0] WPEN — Write Protect Enable
    0=Disables the Write Protect if WPKEY corresponds to 0x858365 ("USA" in ACII); 1=Enables the Write Protect if WPKEY corresponds to 0x858365 ("USA" in ACII)
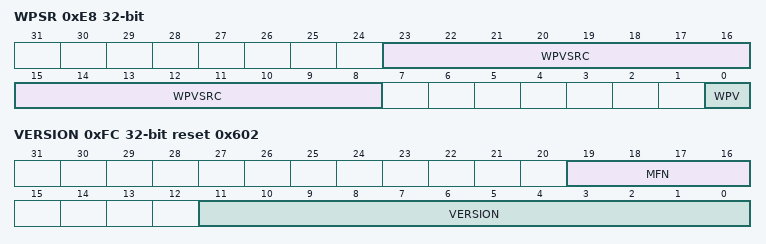
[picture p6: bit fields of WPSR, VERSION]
0xE8 WPSR ro — Write Protect Status Register
  [23:8] WPVSRC — Write Protect Violation Source
  [0] WPV — Write Protect Violation Status
    0=No Write Protect Violation has occurred since the last read of the WPSR register; 1=A Write Protect Violation has occurred since the last read of the WPSR register. If this violation is an unauthorized attempt to write a protected register, the associated violation is reported into field WPVSRC
0xFC VERSION ro reset 0x602
  [19:16] MFN, [11:0] VERSION

## Notices in the file
Atmel Microcontroller Software Support
Copyright (c) 2016 Atmel Corporation,
a wholly owned subsidiary of Microchip Technology Inc.
Licensed under the Apache License, Version 2.0 (the "License");
you may not use this file except in compliance with the License.
You may obtain a copy of the Licence at
http://www.apache.org/licenses/LICENSE-2.0
Unless required by applicable law or agreed to in writing, software
distributed under the License is distributed on an "AS IS" BASIS,
WITHOUT WARRANTIES OR CONDITIONS OF ANY KIND, either express or implied.
See the License for the specific language governing permissions and
limitations under the License.
